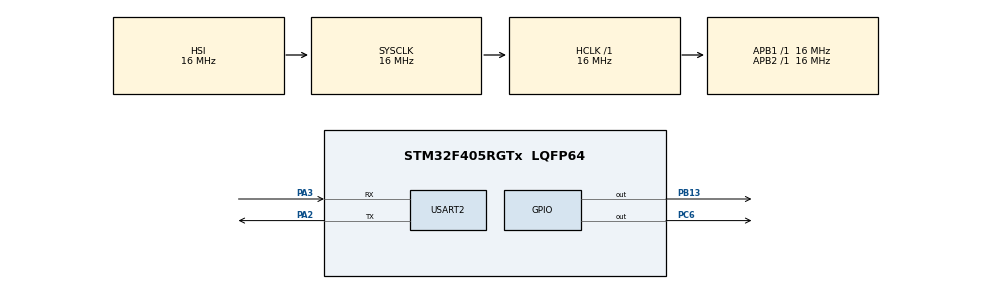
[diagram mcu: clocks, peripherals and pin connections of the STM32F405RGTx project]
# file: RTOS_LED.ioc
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FREERTOS.Tasks01=defaultTask,0,128,StartDefaultTask,Default,NULL,Dynamic,NULL,NULL
Mcu.Family=STM32F4
Mcu.Name=STM32F405RGTx
Mcu.Package=LQFP64
NVIC.PriorityGroup=NVIC_PRIORITYGROUP_4
PA13.Mode=Serial_Wire
PA13.Signal=SYS_JTMS-SWDIO
PA14.Mode=Serial_Wire
PA14.Signal=SYS_JTCK-SWCLK
PA2.Mode=Asynchronous
PA2.Signal=USART2_TX
PA3.Mode=Asynchronous
PA3.Signal=USART2_RX
PB13.Signal=GPIO_Output
PC14-OSC32_IN.Mode=LSE-External-Oscillator
PC14-OSC32_IN.Signal=RCC_OSC32_IN
PC15-OSC32_OUT.Mode=LSE-External-Oscillator
PC15-OSC32_OUT.Signal=RCC_OSC32_OUT
PC6.Signal=GPIO_Output
PH0-OSC_IN.Mode=HSE-External-Oscillator
PH0-OSC_IN.Signal=RCC_OSC_IN
PH1-OSC_OUT.Mode=HSE-External-Oscillator
PH1-OSC_OUT.Signal=RCC_OSC_OUT
ProjectManager.HeapSize=0x200
ProjectManager.StackSize=0x400
ProjectManager.TargetToolchain=STM32CubeIDE
RCC.AHBFreq_Value=16000000
RCC.APB1Freq_Value=16000000
RCC.APB2Freq_Value=16000000
RCC.CortexFreq_Value=16000000
RCC.HSE_VALUE=25000000
RCC.HSI_VALUE=16000000
RCC.SYSCLKFreq_VALUE=16000000
RCC.VCOOutputFreq_Value=192000000
USART2.VirtualMode=VM_ASYNC
VP_FREERTOS_VS_CMSIS_V1.Mode=CMSIS_V1
board=custom

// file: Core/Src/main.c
/* USER CODE BEGIN Header */
/**
  ******************************************************************************
  * @file           : main.c
  * @brief          : Main program body
  ******************************************************************************
  * @attention
  *
  * Copyright (c) 2025 STMicroelectronics.
  * All rights reserved.
  *
  * This software is licensed under terms that can be found in the LICENSE file
  * in the root directory of this software component.
  * If no LICENSE file comes with this software, it is provided AS-IS.
  *
  ******************************************************************************
  */
/* USER CODE END Header */
#include "main.h"
#include "FreeRTOS.h"
#include "task.h"

UART_HandleTypeDef huart2;

void SystemClock_Config(void);
static void MX_GPIO_Init(void);
static void MX_USART2_UART_Init(void);

/* USER CODE BEGIN PFP */
void LEDTask1(void *pvParameters);
void LEDTask2(void *pvParameters);
/* USER CODE END PFP */

/* USER CODE BEGIN 0 */
typedef struct
{
	GPIO_TypeDef *port;
	uint16_t pin;
	uint32_t delay;
}LED_config_t;
static LED_config_t LED1 = {GPIOC , GPIO_PIN_6,500};
static LED_config_t LED2 = {GPIOB , GPIO_PIN_13,2000};
uint8_t led1[]="LED 1 Blinks\n\r";
uint8_t led2[]="LED 2 Blinks\n\r";
/* USER CODE END 0 */

int main(void)
{

  /* MCU Configuration--------------------------------------------------------*/

  /* Reset of all peripherals, Initializes the Flash interface and the Systick. */
  HAL_Init();

  /* Configure the system clock */
  SystemClock_Config();

  /* Initialize all configured peripherals */
  MX_GPIO_Init();
  MX_USART2_UART_Init();

  /* Create the thread(s) */
  /* definition and creation of defaultTask */
  xTaskCreate(LEDTask1,"LED1",128,&LED1,1,NULL);
  xTaskCreate(LEDTask2,"LED2",128,&LED2,1,NULL);

  /* Start scheduler */
  vTaskStartScheduler();

  /* We should never get here as control is now taken by the scheduler */

  /* Infinite loop */
  while (1)
  {

  }
}

void SystemClock_Config(void)
{
  RCC_OscInitTypeDef RCC_OscInitStruct = {0};
  RCC_ClkInitTypeDef RCC_ClkInitStruct = {0};

  /** Configure the main internal regulator output voltage
  */
  __HAL_RCC_PWR_CLK_ENABLE();
  __HAL_PWR_VOLTAGESCALING_CONFIG(PWR_REGULATOR_VOLTAGE_SCALE1);

  /** Initializes the RCC Oscillators according to the specified parameters
  * in the RCC_OscInitTypeDef structure.
  */
  RCC_OscInitStruct.OscillatorType = RCC_OSCILLATORTYPE_HSI;
  RCC_OscInitStruct.HSIState = RCC_HSI_ON;
  RCC_OscInitStruct.HSICalibrationValue = RCC_HSICALIBRATION_DEFAULT;
  RCC_OscInitStruct.PLL.PLLState = RCC_PLL_NONE;
  if (HAL_RCC_OscConfig(&RCC_OscInitStruct) != HAL_OK)
  {
    Error_Handler();
  }

  /** Initializes the CPU, AHB and APB buses clocks
  */
  RCC_ClkInitStruct.ClockType = RCC_CLOCKTYPE_HCLK|RCC_CLOCKTYPE_SYSCLK
                              |RCC_CLOCKTYPE_PCLK1|RCC_CLOCKTYPE_PCLK2;
  RCC_ClkInitStruct.SYSCLKSource = RCC_SYSCLKSOURCE_HSI;
  RCC_ClkInitStruct.AHBCLKDivider = RCC_SYSCLK_DIV1;
  RCC_ClkInitStruct.APB1CLKDivider = RCC_HCLK_DIV1;
  RCC_ClkInitStruct.APB2CLKDivider = RCC_HCLK_DIV1;

  if (HAL_RCC_ClockConfig(&RCC_ClkInitStruct, FLASH_LATENCY_0) != HAL_OK)
  {
    Error_Handler();
  }
}

static void MX_USART2_UART_Init(void)
{

  huart2.Instance = USART2;
  huart2.Init.BaudRate = 115200;
  huart2.Init.WordLength = UART_WORDLENGTH_8B;
  huart2.Init.StopBits = UART_STOPBITS_1;
  huart2.Init.Parity = UART_PARITY_NONE;
  huart2.Init.Mode = UART_MODE_TX_RX;
  huart2.Init.HwFlowCtl = UART_HWCONTROL_NONE;
  huart2.Init.OverSampling = UART_OVERSAMPLING_16;
  if (HAL_UART_Init(&huart2) != HAL_OK)
  {
    Error_Handler();
  }

}

static void MX_GPIO_Init(void)
{
  GPIO_InitTypeDef GPIO_InitStruct = {0};

  /* GPIO Ports Clock Enable */
  __HAL_RCC_GPIOC_CLK_ENABLE();
  __HAL_RCC_GPIOH_CLK_ENABLE();
  __HAL_RCC_GPIOA_CLK_ENABLE();
  __HAL_RCC_GPIOB_CLK_ENABLE();

  /*Configure GPIO pin Output Level */
  HAL_GPIO_WritePin(GPIOB, GPIO_PIN_13, GPIO_PIN_RESET);

  /*Configure GPIO pin Output Level */
  HAL_GPIO_WritePin(GPIOC, GPIO_PIN_6, GPIO_PIN_RESET);

  /*Configure GPIO pin : PB13 */
  GPIO_InitStruct.Pin = GPIO_PIN_13;
  GPIO_InitStruct.Mode = GPIO_MODE_OUTPUT_PP;
  GPIO_InitStruct.Pull = GPIO_NOPULL;
  GPIO_InitStruct.Speed = GPIO_SPEED_FREQ_LOW;
  HAL_GPIO_Init(GPIOB, &GPIO_InitStruct);

  /*Configure GPIO pin : PC6 */
  GPIO_InitStruct.Pin = GPIO_PIN_6;
  GPIO_InitStruct.Mode = GPIO_MODE_OUTPUT_PP;
  GPIO_InitStruct.Pull = GPIO_NOPULL;
  GPIO_InitStruct.Speed = GPIO_SPEED_FREQ_LOW;
  HAL_GPIO_Init(GPIOC, &GPIO_InitStruct);

}

void LEDTask1(void *pvParameters)
{
	LED_config_t *fun1=(LED_config_t*)pvParameters;
	while(1)
	{
		HAL_GPIO_TogglePin(fun1->port,fun1->pin);
		HAL_UART_Transmit(&huart2,(uint8_t*)led1,sizeof(led1)-1,100);
		vTaskDelay(fun1->delay);
	}
}
void LEDTask2(void *pvParameters)
{
	LED_config_t *fun1=(LED_config_t*)pvParameters;
	while(1)
	{
		HAL_GPIO_TogglePin(fun1->port,fun1->pin);
		HAL_UART_Transmit(&huart2,(uint8_t*)led2,sizeof(led2)-1,100);
		vTaskDelay(fun1->delay);
	}
}
void Error_Handler(void)
{
  __disable_irq();
  while (1)
  {
  }
}
